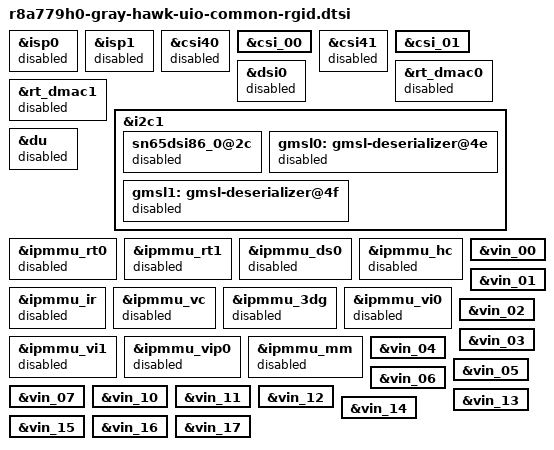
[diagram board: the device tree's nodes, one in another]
// SPDX-License-Identifier: (GPL-2.0-only OR BSD-2-Clause)
/*
 * UIO Device Tree Source for the common parts shared by the Gray Hawk BreakOut
 * and Gray Hawk Single boards
 *
 * Copyright (C) 2024 Renesas Electronics Corp.
 */

#include "r8a779h0-gray-hawk-common-rgid.dtsi"

&isp0 {
	status = "disabled";
};

&isp1 {
	status = "disabled";
};

&csi40 {
	status = "disabled";
};

&csi_00 {
};

&csi41 {
	status = "disabled";
};

&csi_01 {
};

&rt_dmac0 {
	status = "disabled";
};

&rt_dmac1 {
	status = "disabled";
};

&dsi0 {
	status = "disabled";
};

&i2c1 {
	sn65dsi86_0@2c {
		status = "disabled";
	};

	gmsl0: gmsl-deserializer@4e {
		status = "disabled";
	};

	gmsl1: gmsl-deserializer@4f {
		status = "disabled";
	};
};

&du {
	status = "disabled";
};

&ipmmu_rt0 {
	status = "disabled";
};

&ipmmu_rt1 {
	status = "disabled";
};

&ipmmu_ds0 {
	status = "disabled";
};

&ipmmu_hc {
	status = "disabled";
};

&ipmmu_ir {
	status = "disabled";
};

&ipmmu_vc {
	status = "disabled";
};

&ipmmu_3dg {
	status = "disabled";
};

&ipmmu_vi0 {
	status = "disabled";
};

&ipmmu_vi1 {
	status = "disabled";
};

&ipmmu_vip0 {
	status = "disabled";
};

&ipmmu_mm {
	status = "disabled";
};

&vin_00 {
};

&vin_01 {
};

&vin_02 {
};

&vin_03 {
};

&vin_04 {
};

&vin_05 {
};

&vin_06 {
};

&vin_07 {
};

&vin_10 {
};

&vin_11 {
};

&vin_12 {
};

&vin_13 {
};

&vin_14 {
};

&vin_15 {
};

&vin_16 {
};

&vin_17 {
};
